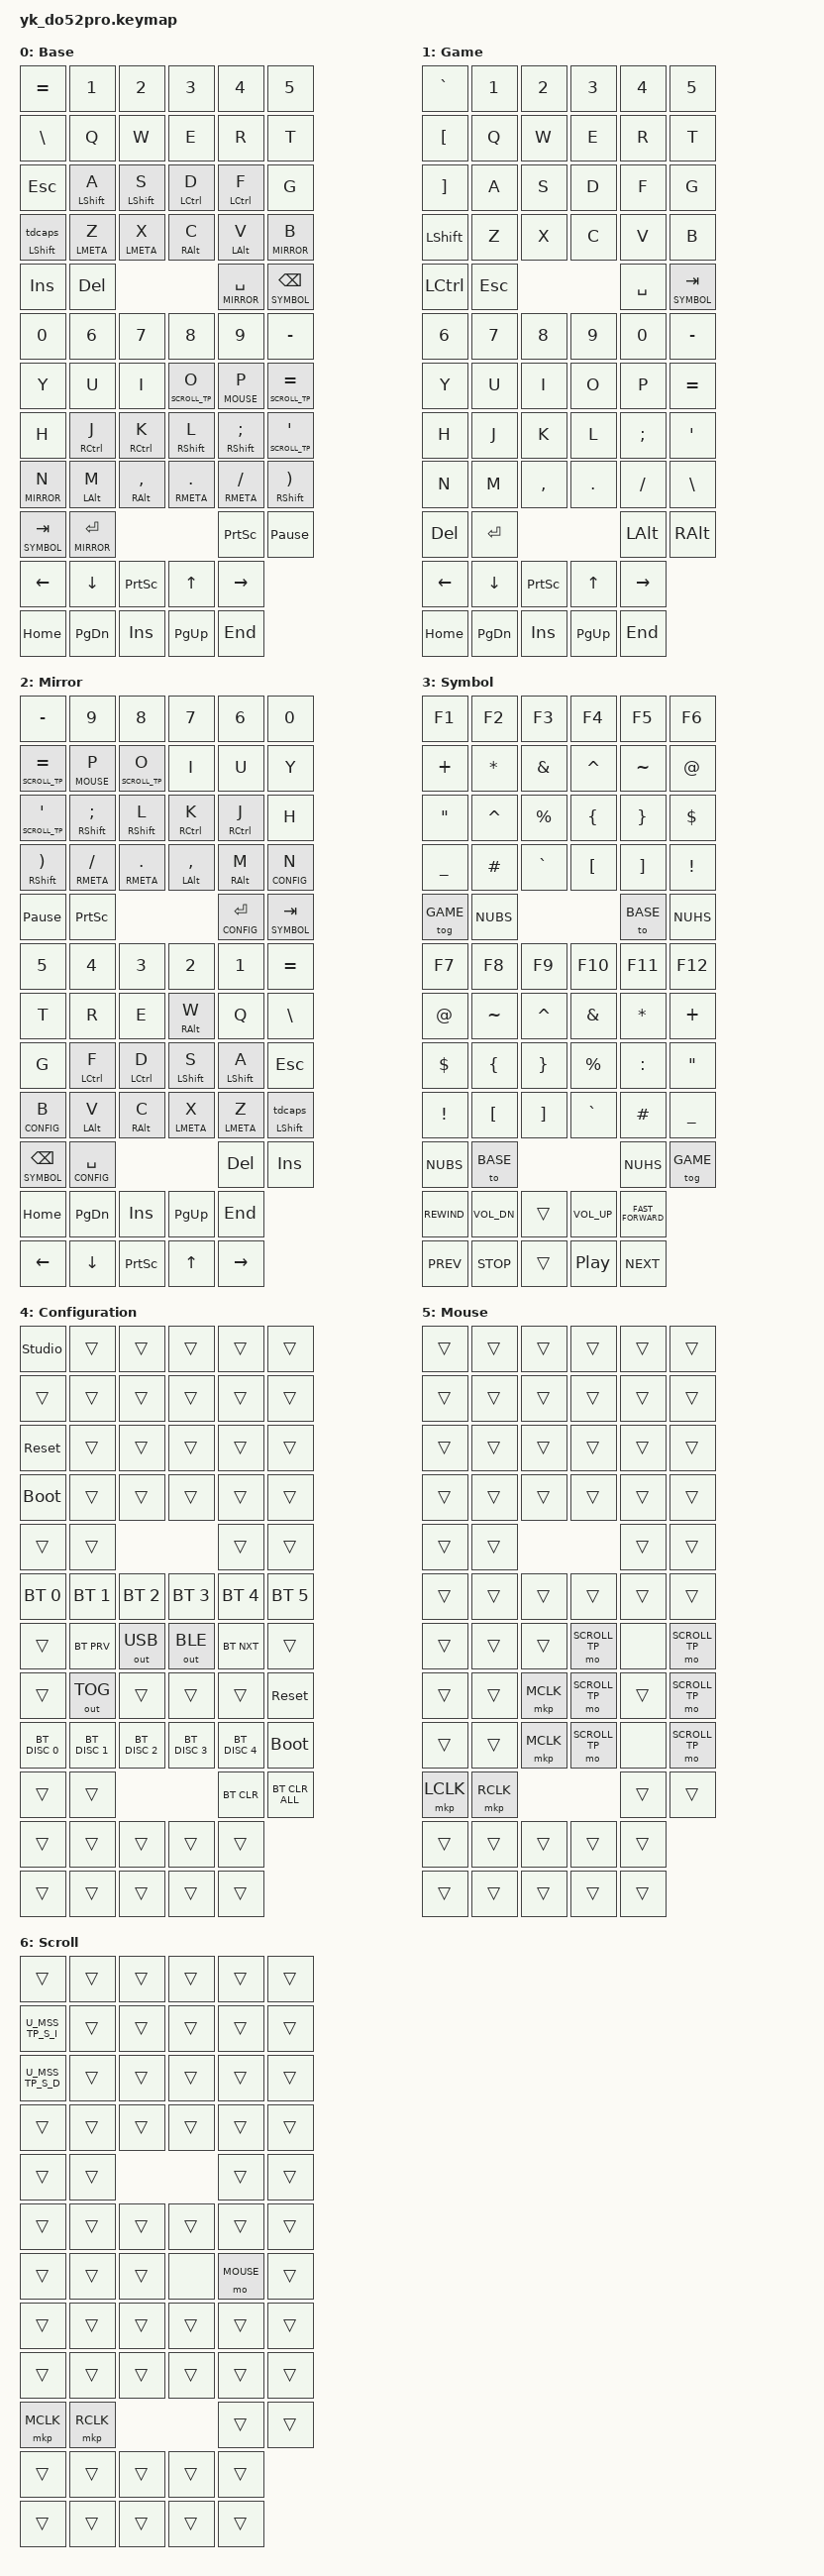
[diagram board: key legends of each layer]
/*
 * Copyright (c) 2020 The ZMK Contributors
 *
 * SPDX-License-Identifier: MIT
 */

#include <behaviors.dtsi>
#include <dt-bindings/zmk/keys.h>

#include "zmk-helpers/helper.h"
#include "include/yk_do52_key.h"

#include <dt-bindings/zmk/bt.h>
#include <dt-bindings/zmk/ext_power.h>
#include <dt-bindings/zmk/outputs.h>


/*
 * Defines to enable/disable features
 *
 * These defines allow us to conditionally enable and disable parts of the keymap config.
 *
 * For example, if we decide to build the firmware without the mouse features, we can
 * disable all the config options that rely on those forks and modules without having
 * to edit the entire keymap file manually every time.
 */

#define HAS_MOUSE_KEYS
#define HAS_MOUSE_TP

#define BASE      0
#define GAME      1
#define MIRROR    2
#define SYMBOL    3
#define CONFIG    4
#define MOUSE     5
#define SCROLL_TP 6

#ifdef HAS_MOUSE_KEYS
  #include <dt-bindings/zmk/mouse.h>
  #include <behaviors/mouse_keys.dtsi>
#endif  // HAS_MOUSE_KEYS

#ifdef HAS_MOUSE_TP
  // We store the trackpoint settings in a separate file
  // to make organization a little easier.
  #include "include/mouse_tp.dtsi"
#endif  // HAS_MOUSE_TP

// key-position labels
#define KEYS_L LT0 LT1 LT2 LT3 LT4 LM0 LM1 LM2 LM3 LM4 LB0 LB1 LB2 LB3 LB4  // left-hand keys
#define KEYS_R RT0 RT1 RT2 RT3 RT4 RM0 RM1 RM2 RM3 RM4 RB0 RB1 RB2 RB3 RB4  // right-hand keys
#define THUMBS LH3 LH2 LH1 LH0 RH0 RH1 RH2 RH3                              // thumb keys


// Adjust layer keys based on enabled features.
//
// This prevents build errors when we build the firmware
// without the mouse keys PR or the TP module.
#ifdef HAS_MOUSE_KEYS
  #define U_THUMB_INNER &mo MOUSE_KEYS
#else
  #define U_THUMB_INNER &none
#endif  // HAS_MOUSE_KEYS

#ifdef HAS_MOUSE_TP
  #define U_TOG_TP_SET &tog MOUSE_TP_SET
#else
  #define U_TOG_TP_SET &none
#endif  // HAS_MOUSE_TP


#define QUICK_TAP_MS 250
#define TAPPING_TERM_MS 150


// Disable line-wrap in your editor to see a "visualization" of the key layouts
/ {


  behaviors {
       /* left-hand HRMs */
        hml: homerow_mods_left {
            compatible = "zmk,behavior-hold-tap";
            flavor = "balanced";
            tapping-term-ms = <TAPPING_TERM_MS>;
            quick-tap-ms = <QUICK_TAP_MS>;                // repeat on tap-into-hold
            require-prior-idle-ms = <15>;
            #binding-cells = <2>;
            bindings = <&kp>, <&kp>;
            hold-trigger-on-release;             // delay positional check until key-release
        };

        /* right-hand HRMs */
        hmr: homerow_mods_right {
            compatible = "zmk,behavior-hold-tap";
            flavor = "balanced";
            tapping-term-ms = <TAPPING_TERM_MS>;
            quick-tap-ms = <QUICK_TAP_MS>;                // repeat on tap-into-hold
            require-prior-idle-ms = <15>;
            #binding-cells = <2>;
            bindings = <&kp>, <&kp>;
            hold-trigger-on-release;             // delay positional check until key-release
        };
        tl: thumb_layer {
            compatible = "zmk,behavior-hold-tap";
             flavor = "balanced";
            tapping-term-ms = <TAPPING_TERM_MS>;
            quick-tap-ms = <QUICK_TAP_MS>;                // repeat on tap-into-hold
            require-prior-idle-ms = <15>;
            #binding-cells = <2>;
            bindings = <&mo>, <&kp>;
            hold-trigger-on-release;             // delay positional check until key-release
        };

        tdcaps: tap_dance_capslock {
            compatible = "zmk,behavior-tap-dance";
            #binding-cells = <0>;
            tapping-term-ms = <TAPPING_TERM_MS>;
            bindings = <&kp LPAR>, <&kp CAPSLOCK>;
        };

        lshift: magic_left_shift {
            compatible = "zmk,behavior-hold-tap";
            flavor = "balanced";
            tapping-term-ms = <TAPPING_TERM_MS>;
            quick-tap-ms = <QUICK_TAP_MS>;                // repeat on tap-into-hold
            require-prior-idle-ms = <15>;
            #binding-cells = <2>;
            bindings = <&kp>, <&tdcaps>;
            hold-trigger-on-release;             // delay positional check until key-release
        };
  };

  keymap {
    compatible = "zmk,keymap";

    Base_layer {
      display-name = "Base";
      bindings = <
//|-----------------|-------------|-------------|------------|-----------------|--------------|
   &kp EQUAL         &kp N1        &kp N2        &kp N3       &kp N4            &kp N5
   &kp BSLH          &kp Q         &kp W         &kp E        &kp R             &kp T
   &kp ESC           &hml LSHIFT A &hml LSHIFT S &hml LCTRL D &hml LCTRL F      &kp G
   &lshift LSHIFT 0  &hml LMETA Z  &hml LMETA X  &hml RALT C  &hml LALT V       &tl MIRROR B
   &kp INS           &kp DEL                                  &tl MIRROR SPACE  &tl SYMBOL BSPC

//|---------------|-------------|----------------|---------------|----------------|-------------|
   &kp N0          &kp N6        &kp N7           &kp N8          &kp N9           &kp MINUS
   &kp Y           &kp U         &kp I            &tl SCROLL_TP O &tl MOUSE P      &tl SCROLL_TP EQUAL
   &kp H           &hmr RCTRL J  &hmr RCTRL K     &hmr RSHIFT L   &hmr RSHIFT SEMI &tl SCROLL_TP SQT
   &tl MIRROR N    &hmr LALT  M  &hmr RALT  COMMA &hmr RMETA DOT  &hmr RMETA FSLH  &hmr RSHFT RPAR
   &tl SYMBOL TAB  &tl MIRROR RET                                 &kp PRINTSCREEN  &kp PAUSE_BREAK

// DPAD
// Left   Down       Middle      Up         Right
&kp LEFT  &kp DOWN   &kp PSCRN   &kp UP     &kp RIGHT
&kp HOME  &kp PG_DN  &kp INS     &kp PG_UP  &kp END
      >;
    };

      Game_layer {
      display-name = "Game";
      bindings = <
//|-----------------|-------------|-----------|------------|-----------------|----------------|
   &kp GRAVE         &kp N1        &kp N2      &kp N3       &kp N4            &kp N5
   &kp LBKT          &kp Q         &kp W       &kp E        &kp R             &kp T
   &kp RBKT          &kp A         &kp S       &kp D        &kp F             &kp G
   &kp LSHFT         &kp Z         &kp X       &kp C        &kp V             &kp B
   &kp LCTRL         &kp ESC                                &kp SPACE         &tl SYMBOL TAB

//|---------------|-------------|------------|---------------|---------------|------------|
   &kp N6          &kp N7        &kp N8       &kp N9          &kp N0          &kp MINUS
   &kp Y           &kp U         &kp I        &kp O           &kp P           &kp EQUAL
   &kp H           &kp J         &kp K        &kp L           &kp SEMI        &kp SQT
   &kp N           &kp M         &kp COMMA    &kp DOT         &kp FSLH        &kp BSLH
   &kp DEL         &kp RET                                    &kp LALT        &kp RALT

// DPAD
// Left   Down       Middle      Up          Right
&kp LEFT  &kp DOWN   &kp PSCRN   &kp UP     &kp RIGHT
&kp HOME  &kp PG_DN  &kp INS     &kp PG_UP  &kp END
      >;
    };

    Mirror_layer {
      display-name = "Mirror";
         bindings = <
//|-------------------|----------------|---------------|----------------|--------------|--------------|
   &kp MINUS           &kp N9           &kp N8          &kp N7           &kp N6         &kp N0
   &tl SCROLL_TP EQUAL &tl MOUSE P      &tl SCROLL_TP O &kp I            &kp U          &kp Y
   &tl SCROLL_TP SQT   &hmr RSHIFT SEMI &hmr RSHIFT L   &hmr RCTRL K     &hmr RCTRL J   &kp H
   &hmr RSHFT RPAR     &hmr RMETA FSLH  &hmr RMETA DOT  &hmr LALT  COMMA &hmr RALT  M   &tl CONFIG N
   &kp PAUSE_BREAK     &kp PRINTSCREEN                                   &tl CONFIG RET &tl SYMBOL TAB

//|-----------------|-----------------|------------|-------------|-------------|---------------|
   &kp N5            &kp N4            &kp N3       &kp N2        &kp N1        &kp EQUAL
   &kp T             &kp R             &kp E        &hml RALT W   &kp Q         &kp BSLH
   &kp G             &hml LCTRL F      &hml LCTRL D &hml LSHIFT S &hml LSHIFT A &kp ESC
   &tl CONFIG B      &hml LALT V       &hml RALT C  &hml LMETA X  &hml LMETA Z  &lshift LSHIFT 0
   &tl SYMBOL BSPC   &tl CONFIG SPACE                             &kp DEL       &kp INS

// DPAD
// Left   Down       Middle      Up         Right
&kp HOME  &kp PG_DN  &kp INS     &kp PG_UP  &kp END
&kp LEFT  &kp DOWN   &kp PSCRN   &kp UP     &kp RIGHT
      >;
    };

    Symbol_layer {
      display-name = "Symbol";
          bindings = <
//|--------------|-------------|--------------|-----------|---------------|---------------|
   &kp F1         &kp F2        &kp F3         &kp F4      &kp F5          &kp F6
   &kp PLUS       &kp STAR      &kp AMPERSAND  &kp CARET   &kp TILDE       &kp AT
   &kp DQT        &kp CARET     &kp PERCENT    &kp LBRC    &kp RBRC        &kp DOLLAR
   &kp UNDER      &kp HASH      &kp GRAVE      &kp LBKT    &kp RBKT        &kp EXCL
   &tog GAME      &kp NUBS                                 &to BASE        &kp NUHS

//|---------------|-------------|-------------|-------------|---------------|------------|
   &kp F7          &kp F8        &kp F9        &kp F10       &kp F11         &kp F12
   &kp AT          &kp TILDE     &kp CARET     &kp AMPERSAND &kp STAR        &kp PLUS
   &kp DOLLAR      &kp LBRC      &kp RBRC      &kp PERCENT   &kp COLON       &kp DQT
   &kp EXCL        &kp LBKT      &kp RBKT      &kp GRAVE     &kp HASH        &kp UNDER
   &kp NUBS        &to BASE                                  &kp NUHS        &tog GAME

// DPAD
// Left           Down           Middle   Up                 Right
   &kp C_REWIND   &kp C_VOL_DN   &trans   &kp C_VOL_UP       &kp C_FAST_FORWARD
   &kp C_PREV     &kp C_STOP     &trans   &kp C_PLAY_PAUSE   &kp C_NEXT
      >;
    };

    Config_layer {
      display-name = "Configuration";
      bindings = <
//|---------------|-------------|-----------|-----------|---------------|---------------|
   &studio_unlock  &trans        &trans      &trans      &trans          &trans
   &trans          &trans        &trans      &trans      &trans          &trans
   &sys_reset      &trans        &trans      &trans      &trans          &trans
   &bootloader     &trans        &trans      &trans      &trans          &trans
   &trans          &trans                                &trans          &trans

//|---------------|-------------|-------------|-------------|---------------|------------|
   &bt BT_SEL 0    &bt BT_SEL 1  &bt BT_SEL 2  &bt BT_SEL 3  &bt BT_SEL 4    &bt BT_SEL 5
   &trans          &bt BT_PRV    &out OUT_USB  &out OUT_BLE  &bt BT_NXT      &trans
   &trans          &out OUT_TOG  &trans        &trans        &trans          &sys_reset
   &bt BT_DISC 0   &bt BT_DISC 1 &bt BT_DISC 2 &bt BT_DISC 3 &bt BT_DISC 4   &bootloader
   &trans          &trans                                    &bt BT_CLR      &bt BT_CLR_ALL

// DPAD
// Left    Down    Middle      Up      Right
&trans     &trans  &trans      &trans  &trans
&trans     &trans  &trans      &trans  &trans
      >;
    };

     Mouse_layer {
      display-name = "Mouse";
      bindings = <
//|------------|-------------|-----------|-----------|---------------|------|
   &trans       &trans        &trans      &trans      &trans          &trans
   &trans       &trans        &trans      &trans      &trans          &trans
   &trans       &trans        &trans      &trans      &trans          &trans
   &trans       &trans        &trans      &trans      &trans          &trans
   &trans       &trans                                &trans          &trans

//|---------------|-------------|-----------|---------------|---------------|-------------|
   &trans          &trans        &trans      &trans          &trans          &trans
   &trans          &trans        &trans      &mo SCROLL_TP   &none           &mo SCROLL_TP
   &trans          &trans        &mkp MCLK   &mo SCROLL_TP   &trans          &mo SCROLL_TP
   &trans          &trans        &mkp MCLK   &mo SCROLL_TP   &none           &mo SCROLL_TP
   &mkp LCLK       &mkp RCLK                                 &trans          &trans

// DPAD
// Left    Down    Middle      Up      Right
&trans     &trans  &trans      &trans  &trans
&trans     &trans  &trans      &trans  &trans
         >;
       };

     Scroll_layer {
      display-name = "Scroll";
      bindings = <
//|-------------|-------------|-----------|-----------|---------------|---------------|
   &trans        &trans        &trans      &trans      &trans          &trans
   U_MSS_TP_S_I  &trans        &trans      &trans      &trans          &trans
   U_MSS_TP_S_D  &trans        &trans      &trans      &trans          &trans
   &trans        &trans        &trans      &trans      &trans          &trans
   &trans        &trans                                &trans          &trans

//|---------------|-------------|-----------|-------------|---------------|------------|
   &trans          &trans        &trans      &trans        &trans          &trans
   &trans          &trans        &trans      &none         &mo MOUSE       &trans
   &trans          &trans        &trans      &trans        &trans          &trans
   &trans          &trans        &trans      &trans        &trans          &trans
   &mkp MCLK       &mkp RCLK                               &trans          &trans

// DPAD
// Left     Down    Middle      Up      Right
 &trans     &trans  &trans      &trans  &trans
 &trans     &trans  &trans      &trans  &trans
      >;
    };

  };
};
